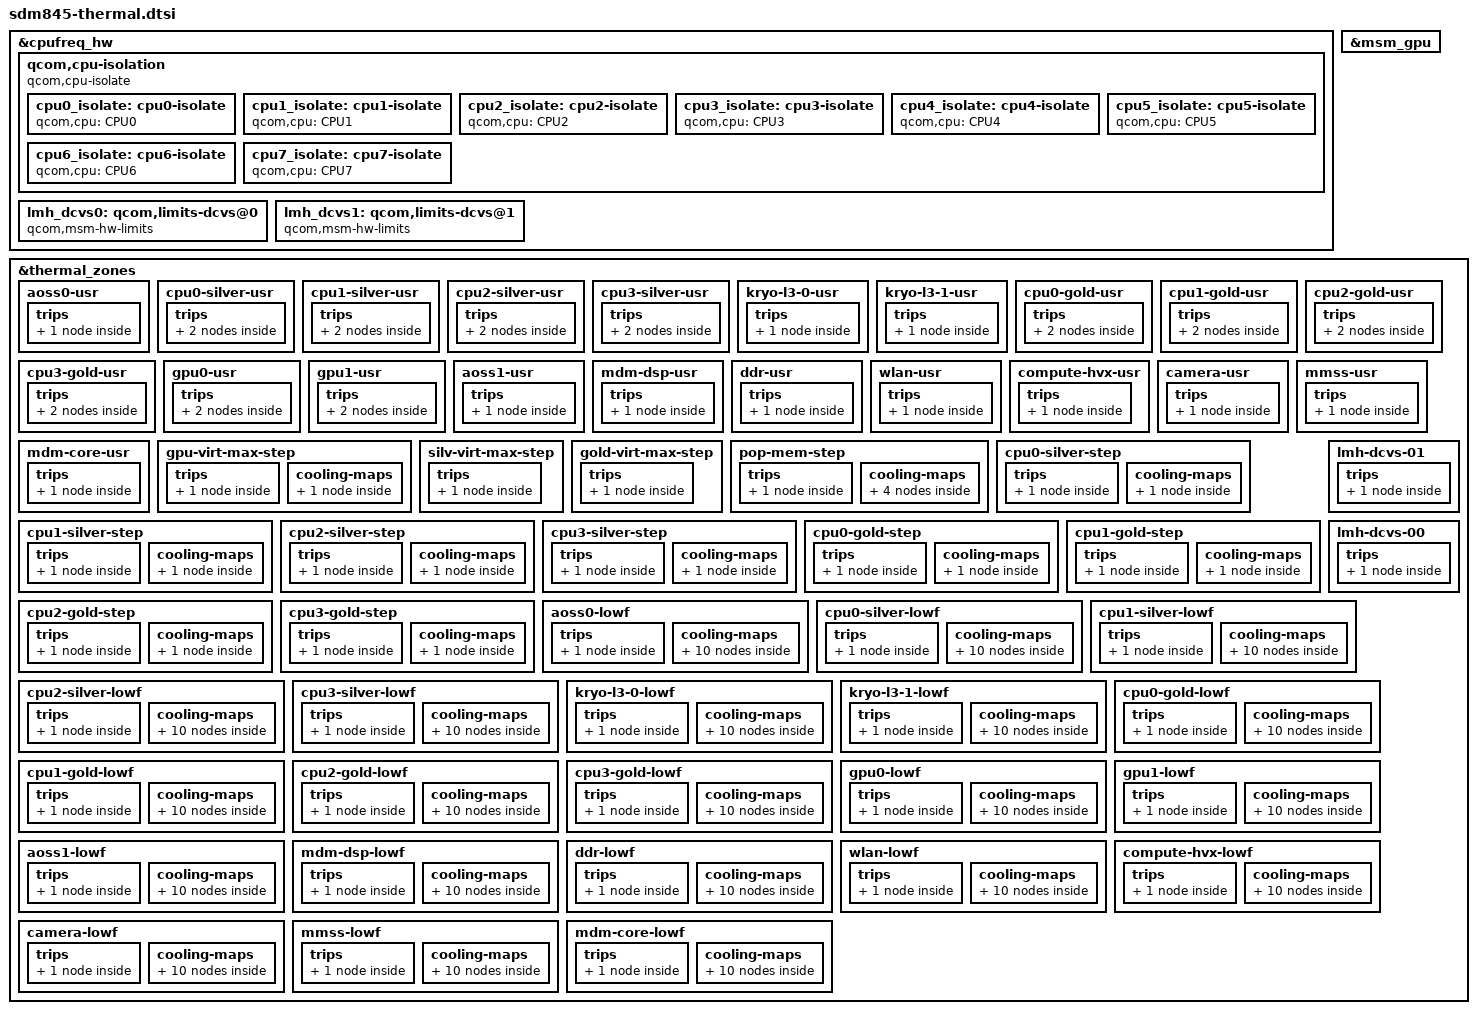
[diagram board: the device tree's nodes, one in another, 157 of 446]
// SPDX-License-Identifier: GPL-2.0-only
/*
 * Copyright (c) 2025, Pavel Dubrova <pashadubrova@gmail.com>
 */

#include <dt-bindings/thermal/thermal.h>

&cpufreq_hw {
	qcom,cpu-isolation {
		compatible = "qcom,cpu-isolate";
		cpu0_isolate: cpu0-isolate {
			qcom,cpu = <&CPU0>;
			#cooling-cells = <2>;
		};

		cpu1_isolate: cpu1-isolate {
			qcom,cpu = <&CPU1>;
			#cooling-cells = <2>;
		};

		cpu2_isolate: cpu2-isolate {
			qcom,cpu = <&CPU2>;
			#cooling-cells = <2>;
		};

		cpu3_isolate: cpu3-isolate {
			qcom,cpu = <&CPU3>;
			#cooling-cells = <2>;
		};

		cpu4_isolate: cpu4-isolate {
			qcom,cpu = <&CPU4>;
			#cooling-cells = <2>;
		};

		cpu5_isolate: cpu5-isolate {
			qcom,cpu = <&CPU5>;
			#cooling-cells = <2>;
		};

		cpu6_isolate: cpu6-isolate {
			qcom,cpu = <&CPU6>;
			#cooling-cells = <2>;
		};

		cpu7_isolate: cpu7-isolate {
			qcom,cpu = <&CPU7>;
			#cooling-cells = <2>;
		};
	};

	lmh_dcvs0: qcom,limits-dcvs@0 {
		compatible = "qcom,msm-hw-limits";
		interrupts = <GIC_SPI 32 IRQ_TYPE_LEVEL_HIGH>;
		reg = <0x17d78800 0x1000>,
		<0x17d43000 0x1000>;
		qcom,affinity = <0>;
		#thermal-sensor-cells = <0>;
		qcom,no-cooling-device-register;
		qcom,legacy-lmh-enable;
	};

	lmh_dcvs1: qcom,limits-dcvs@1 {
		compatible = "qcom,msm-hw-limits";
		interrupts = <GIC_SPI 33 IRQ_TYPE_LEVEL_HIGH>;
		qcom,affinity = <1>;
		reg = <0x17d70800 0x1000>,
		<0x17d45800 0x1000>;
		#thermal-sensor-cells = <0>;
		isens_vref_0p8-supply = <&pm8998_l1_ao>;
		isens-vref-0p8-settings = <880000 880000 20000>;
		qcom,no-cooling-device-register;
		qcom,legacy-lmh-enable;
	};
};

#include "sdm845-thermal-modem.dtsi"
#include "sdm845-thermal-overlay.dtsi"

&msm_gpu {
	#cooling-cells = <2>;
};

&thermal_zones {
	aoss0-usr {
		polling-delay-passive = <0>;
		polling-delay = <0>;
		thermal-governor = "user_space";
		thermal-sensors = <&tsens0 0>;
		wake-capable-sensor;
		trips {
			active-config0 {
				temperature = <125000>;
				hysteresis = <1000>;
				type = "passive";
			};
		};
	};

	cpu0-silver-usr {
		polling-delay-passive = <0>;
		polling-delay = <0>;
		thermal-governor = "user_space";
		thermal-sensors = <&tsens0 1>;
		wake-capable-sensor;
		trips {
			active-config0 {
				temperature = <125000>;
				hysteresis = <1000>;
				type = "passive";
			};

			thermal-hal-cfg {
				temperature = <115000>;
				hysteresis = <5000>;
				type = "passive";
			};
		};
	};

	cpu1-silver-usr {
		polling-delay-passive = <0>;
		polling-delay = <0>;
		thermal-governor = "user_space";
		thermal-sensors = <&tsens0 2>;
		wake-capable-sensor;
		trips {
			active-config0 {
				temperature = <125000>;
				hysteresis = <1000>;
				type = "passive";
			};

			thermal-hal-cfg {
				temperature = <115000>;
				hysteresis = <5000>;
				type = "passive";
			};
		};
	};

	cpu2-silver-usr {
		polling-delay-passive = <0>;
		polling-delay = <0>;
		thermal-governor = "user_space";
		thermal-sensors = <&tsens0 3>;
		wake-capable-sensor;
		trips {
			active-config0 {
				temperature = <125000>;
				hysteresis = <1000>;
				type = "passive";
			};

			thermal-hal-cfg {
				temperature = <115000>;
				hysteresis = <5000>;
				type = "passive";
			};
		};
	};

	cpu3-silver-usr {
		polling-delay-passive = <0>;
		polling-delay = <0>;
		thermal-sensors = <&tsens0 4>;
		wake-capable-sensor;
		thermal-governor = "user_space";
		trips {
			active-config0 {
				temperature = <125000>;
				hysteresis = <1000>;
				type = "passive";
			};

			thermal-hal-cfg {
				temperature = <115000>;
				hysteresis = <5000>;
				type = "passive";
			};
		};
	};

	kryo-l3-0-usr {
		polling-delay-passive = <0>;
		polling-delay = <0>;
		thermal-sensors = <&tsens0 5>;
		wake-capable-sensor;
		thermal-governor = "user_space";
		trips {
			active-config0 {
				temperature = <125000>;
				hysteresis = <1000>;
				type = "passive";
			};
		};
	};

	kryo-l3-1-usr {
		polling-delay-passive = <0>;
		polling-delay = <0>;
		thermal-sensors = <&tsens0 6>;
		wake-capable-sensor;
		thermal-governor = "user_space";
		trips {
			active-config0 {
				temperature = <125000>;
				hysteresis = <1000>;
				type = "passive";
			};
		};
	};

	cpu0-gold-usr {
		polling-delay-passive = <0>;
		polling-delay = <0>;
		thermal-sensors = <&tsens0 7>;
		wake-capable-sensor;
		thermal-governor = "user_space";
		trips {
			active-config0 {
				temperature = <125000>;
				hysteresis = <1000>;
				type = "passive";
			};

			thermal-hal-cfg {
				temperature = <115000>;
				hysteresis = <5000>;
				type = "passive";
			};
		};
	};

	cpu1-gold-usr {
		polling-delay-passive = <0>;
		polling-delay = <0>;
		thermal-sensors = <&tsens0 8>;
		wake-capable-sensor;
		thermal-governor = "user_space";
		trips {
			active-config0 {
				temperature = <125000>;
				hysteresis = <1000>;
				type = "passive";
			};

			thermal-hal-cfg {
				temperature = <115000>;
				hysteresis = <5000>;
				type = "passive";
			};
		};
	};

	cpu2-gold-usr {
		polling-delay-passive = <0>;
		polling-delay = <0>;
		thermal-sensors = <&tsens0 9>;
		wake-capable-sensor;
		thermal-governor = "user_space";
		trips {
			active-config0 {
				temperature = <125000>;
				hysteresis = <1000>;
				type = "passive";
			};

			thermal-hal-cfg {
				temperature = <115000>;
				hysteresis = <5000>;
				type = "passive";
			};
		};
	};

	cpu3-gold-usr {
		polling-delay-passive = <0>;
		polling-delay = <0>;
		thermal-sensors = <&tsens0 10>;
		wake-capable-sensor;
		thermal-governor = "user_space";
		trips {
			active-config0 {
				temperature = <125000>;
				hysteresis = <1000>;
				type = "passive";
			};

			thermal-hal-cfg {
				temperature = <115000>;
				hysteresis = <5000>;
				type = "passive";
			};
		};
	};

	gpu0-usr {
		polling-delay-passive = <0>;
		polling-delay = <0>;
		thermal-sensors = <&tsens0 11>;
		wake-capable-sensor;
		thermal-governor = "user_space";
		trips {
			active-config0 {
				temperature = <125000>;
				hysteresis = <1000>;
				type = "passive";
			};

			thermal-hal-cfg {
				temperature = <115000>;
				hysteresis = <5000>;
				type = "passive";
			};
		};
	};

	gpu1-usr {
		polling-delay-passive = <0>;
		polling-delay = <0>;
		thermal-governor = "user_space";
		thermal-sensors = <&tsens0 12>;
		wake-capable-sensor;
		trips {
			active-config0 {
				temperature = <125000>;
				hysteresis = <1000>;
				type = "passive";
			};

			thermal-hal-cfg {
				temperature = <115000>;
				hysteresis = <5000>;
				type = "passive";
			};
		};
	};

	aoss1-usr {
		polling-delay-passive = <0>;
		polling-delay = <0>;
		thermal-sensors = <&tsens1 0>;
		wake-capable-sensor;
		thermal-governor = "user_space";
		trips {
			active-config0 {
				temperature = <125000>;
				hysteresis = <1000>;
				type = "passive";
			};
		};
	};

	mdm-dsp-usr {
		polling-delay-passive = <0>;
		polling-delay = <0>;
		thermal-sensors = <&tsens1 1>;
		wake-capable-sensor;
		thermal-governor = "user_space";
		trips {
			active-config0 {
				temperature = <125000>;
				hysteresis = <1000>;
				type = "passive";
			};
		};
	};



	ddr-usr {
		polling-delay-passive = <0>;
		polling-delay = <0>;
		thermal-sensors = <&tsens1 2>;
		wake-capable-sensor;
		thermal-governor = "user_space";
		trips {
			active-config0 {
				temperature = <125000>;
				hysteresis = <1000>;
				type = "passive";
			};
		};
	};

	wlan-usr {
		polling-delay-passive = <0>;
		polling-delay = <0>;
		thermal-sensors = <&tsens1 3>;
		wake-capable-sensor;
		thermal-governor = "user_space";
		trips {
			active-config0 {
				temperature = <125000>;
				hysteresis = <1000>;
				type = "passive";
			};
		};
	};

	compute-hvx-usr {
		polling-delay-passive = <0>;
		polling-delay = <0>;
		thermal-sensors = <&tsens1 4>;
		wake-capable-sensor;
		thermal-governor = "user_space";
		trips {
			active-config0 {
				temperature = <125000>;
				hysteresis = <1000>;
				type = "passive";
			};
		};
	};

	camera-usr {
		polling-delay-passive = <0>;
		polling-delay = <0>;
		thermal-sensors = <&tsens1 5>;
		wake-capable-sensor;
		thermal-governor = "user_space";
		trips {
			active-config0 {
				temperature = <125000>;
				hysteresis = <1000>;
				type = "passive";
			};
		};
	};

	mmss-usr {
		polling-delay-passive = <0>;
		polling-delay = <0>;
		thermal-sensors = <&tsens1 6>;
		wake-capable-sensor;
		thermal-governor = "user_space";
		trips {
			active-config0 {
				temperature = <125000>;
				hysteresis = <1000>;
				type = "passive";
			};
		};
	};

	mdm-core-usr {
		polling-delay-passive = <0>;
		polling-delay = <0>;
		thermal-sensors = <&tsens1 7>;
		wake-capable-sensor;
		thermal-governor = "user_space";
		trips {
			active-config0 {
				temperature = <125000>;
				hysteresis = <1000>;
				type = "passive";
			};
		};
	};

	gpu-virt-max-step {
		polling-delay-passive = <10>;
		polling-delay = <100>;
		thermal-governor = "step_wise";
		wake-capable-sensor;
		trips {
			gpu_trip0: gpu-trip0 {
				temperature = <95000>;
				hysteresis = <0>;
				type = "passive";
			};
		};
		cooling-maps {
			gpu_cdev0 {
				trip = <&gpu_trip0>;
				cooling-device =
				<&msm_gpu 0 THERMAL_NO_LIMIT>;
			};
		};
	};

	silv-virt-max-step {
		polling-delay-passive = <0>;
		polling-delay = <0>;
		thermal-governor = "step_wise";
		wake-capable-sensor;
		trips {
			silver-trip {
				temperature = <120000>;
				hysteresis = <0>;
				type = "passive";
			};
		};
	};

	gold-virt-max-step {
		polling-delay-passive = <0>;
		polling-delay = <0>;
		thermal-governor = "step_wise";
		wake-capable-sensor;
		trips {
			gold-trip {
				temperature = <120000>;
				hysteresis = <0>;
				type = "passive";
			};
		};
	};

	pop-mem-step {
		polling-delay-passive = <10>;
		polling-delay = <0>;
		thermal-sensors = <&tsens1 2>;
		wake-capable-sensor;
		thermal-governor = "step_wise";
		trips {
			pop_trip: pop-trip {
				temperature = <95000>;
				hysteresis = <0>;
				type = "passive";
			};
		};
		cooling-maps {
			pop_cdev4 {
				trip = <&pop_trip>;
				cooling-device =
				<&CPU4 THERMAL_NO_LIMIT
				(THERMAL_MAX_LIMIT-1)>;
			};
			pop_cdev5 {
				trip = <&pop_trip>;
				cooling-device =
				<&CPU5 THERMAL_NO_LIMIT
				(THERMAL_MAX_LIMIT-1)>;
			};
			pop_cdev6 {
				trip = <&pop_trip>;
				cooling-device =
				<&CPU6 THERMAL_NO_LIMIT
				(THERMAL_MAX_LIMIT-1)>;
			};
			pop_cdev7 {
				trip = <&pop_trip>;
				cooling-device =
				<&CPU7 THERMAL_NO_LIMIT
				(THERMAL_MAX_LIMIT-1)>;
			};
		};
	};

	cpu0-silver-step {
		polling-delay-passive = <100>;
		polling-delay = <0>;
		thermal-sensors = <&tsens0 1>;
		wake-capable-sensor;
		thermal-governor = "step_wise";
		trips {
			emerg_config0: emerg-config0 {
				temperature = <110000>;
				hysteresis = <10000>;
				type = "passive";
			};
		};
		cooling-maps {
			emerg_cdev0 {
				trip = <&emerg_config0>;
				cooling-device = <&cpu0_isolate 1 1>;
			};
		};
	};

	cpu1-silver-step {
		polling-delay-passive = <100>;
		polling-delay = <0>;
		thermal-sensors = <&tsens0 2>;
		wake-capable-sensor;
		thermal-governor = "step_wise";
		trips {
			emerg_config1: emerg-config1 {
				temperature = <110000>;
				hysteresis = <10000>;
				type = "passive";
			};
		};
		cooling-maps {
			emerg_cdev1 {
				trip = <&emerg_config1>;
				cooling-device = <&cpu1_isolate 1 1>;
			};
		};
	};

	cpu2-silver-step {
		polling-delay-passive = <100>;
		polling-delay = <0>;
		thermal-sensors = <&tsens0 3>;
		wake-capable-sensor;
		thermal-governor = "step_wise";
		trips {
			emerg_config2: emerg-config2 {
				temperature = <110000>;
				hysteresis = <10000>;
				type = "passive";
			};
		};
		cooling-maps {
			emerg_cdev2 {
				trip = <&emerg_config2>;
				cooling-device = <&cpu2_isolate 1 1>;
			};
		};
	};

	cpu3-silver-step {
		polling-delay-passive = <100>;
		polling-delay = <0>;
		thermal-sensors = <&tsens0 4>;
		wake-capable-sensor;
		thermal-governor = "step_wise";
		trips {
			emerg_config3: emerg-config3 {
				temperature = <110000>;
				hysteresis = <10000>;
				type = "passive";
			};
		};
		cooling-maps {
			emerg_cdev3 {
				trip = <&emerg_config3>;
				cooling-device = <&cpu3_isolate 1 1>;
			};
		};
	};

	cpu0-gold-step {
		polling-delay-passive = <100>;
		polling-delay = <0>;
		thermal-sensors = <&tsens0 7>;
		wake-capable-sensor;
		thermal-governor = "step_wise";
		trips {
			emerg_config4: emerg-config4 {
				temperature = <110000>;
				hysteresis = <10000>;
				type = "passive";
			};
		};
		cooling-maps {
			emerg_cdev4 {
				trip = <&emerg_config4>;
				cooling-device = <&cpu4_isolate 1 1>;
			};
		};
	};

	cpu1-gold-step {
		polling-delay-passive = <100>;
		polling-delay = <0>;
		thermal-sensors = <&tsens0 8>;
		wake-capable-sensor;
		thermal-governor = "step_wise";
		trips {
			emerg_config5: emerg-config5 {
				temperature = <110000>;
				hysteresis = <10000>;
				type = "passive";
			};
		};
		cooling-maps {
			emerg_cdev5 {
				trip = <&emerg_config5>;
				cooling-device = <&cpu5_isolate 1 1>;
			};
		};
	};

	cpu2-gold-step {
		polling-delay-passive = <100>;
		polling-delay = <0>;
		thermal-sensors = <&tsens0 9>;
		wake-capable-sensor;
		thermal-governor = "step_wise";
		trips {
			emerg_config6: emerg-config6 {
				temperature = <110000>;
				hysteresis = <10000>;
				type = "passive";
			};
		};
		cooling-maps {
			emerg_cdev6 {
				trip = <&emerg_config6>;
				cooling-device = <&cpu6_isolate 1 1>;
			};
		};
	};

	cpu3-gold-step {
		polling-delay-passive = <100>;
		polling-delay = <0>;
		thermal-sensors = <&tsens0 10>;
		wake-capable-sensor;
		thermal-governor = "step_wise";
		trips {
			emerg_config7: emerg-config7 {
				temperature = <110000>;
				hysteresis = <10000>;
				type = "passive";
			};
		};
		cooling-maps {
			emerg_cdev7 {
				trip = <&emerg_config7>;
				cooling-device = <&cpu7_isolate 1 1>;
			};
		};
	};

	lmh-dcvs-01 {
		polling-delay-passive = <0>;
		polling-delay = <0>;
		thermal-governor = "user_space";
		thermal-sensors = <&lmh_dcvs1>;
		wake-capable-sensor;

		trips {
			active-config {
				temperature = <95000>;
				hysteresis = <30000>;
				type = "passive";
			};
		};
	};

	lmh-dcvs-00 {
		polling-delay-passive = <0>;
		polling-delay = <0>;
		thermal-governor = "user_space";
		thermal-sensors = <&lmh_dcvs0>;
		wake-capable-sensor;

		trips {
			active-config {
				temperature = <95000>;
				hysteresis = <30000>;
				type = "passive";
			};
		};
	};
};

&thermal_zones {
		aoss0-lowf {
		polling-delay-passive = <0>;
		polling-delay = <0>;
		thermal-governor = "low_limits_floor";
		thermal-sensors = <&tsens0 0>;
		wake-capable-sensor;
		tracks-low;
		trips {
			aoss0_trip: aoss0-trip {
				temperature = <5000>;
				hysteresis = <5000>;
				type = "passive";
			};
		};
		cooling-maps {
			cpu0_vdd_cdev {
				trip = <&aoss0_trip>;
				cooling-device = <&CPU0 4 4>;
			};
			cpu4_vdd_cdev {
				trip = <&aoss0_trip>;
				cooling-device = <&CPU4 9 9>;
			};
			gpu_vdd_cdev {
				trip = <&aoss0_trip>;
				cooling-device = <&msm_gpu 1 1>;
			};
			cx_vdd_cdev {
				trip = <&aoss0_trip>;
				cooling-device = <&cx_cdev 0 0>;
			};
			mx_vdd_cdev {
				trip = <&aoss0_trip>;
				cooling-device = <&mx_cdev 0 0>;
			};
			ebi_vdd_cdev {
				trip = <&aoss0_trip>;
				cooling-device = <&ebi_cdev 0 0>;
			};
			modem_vdd_cdev {
				trip = <&aoss0_trip>;
				cooling-device = <&modem_vdd 0 0>;
			};
			adsp_vdd_cdev {
				trip = <&aoss0_trip>;
				cooling-device = <&adsp_vdd 0 0>;
			};
			cdsp_vdd_cdev {
				trip = <&aoss0_trip>;
				cooling-device = <&cdsp_vdd 0 0>;
			};
			slpi_vdd_cdev {
				trip = <&aoss0_trip>;
				cooling-device = <&slpi_vdd 0 0>;
			};
		};
	};

	cpu0-silver-lowf {
		polling-delay-passive = <0>;
		polling-delay = <0>;
		thermal-governor = "low_limits_floor";
		thermal-sensors = <&tsens0 1>;
		wake-capable-sensor;
		tracks-low;
		trips {
			cpu0_trip: cpu0-trip {
				temperature = <5000>;
				hysteresis = <5000>;
				type = "passive";
			};
		};
		cooling-maps {
			cpu0_vdd_cdev {
				trip = <&cpu0_trip>;
				cooling-device = <&CPU0 4 4>;
			};
			cpu4_vdd_cdev {
				trip = <&cpu0_trip>;
				cooling-device = <&CPU4 9 9>;
			};
			gpu_vdd_cdev {
				trip = <&cpu0_trip>;
				cooling-device = <&msm_gpu 1 1>;
			};
			cx_vdd_cdev {
				trip = <&cpu0_trip>;
				cooling-device = <&cx_cdev 0 0>;
			};
			mx_vdd_cdev {
				trip = <&cpu0_trip>;
				cooling-device = <&mx_cdev 0 0>;
			};
			ebi_vdd_cdev {
				trip = <&cpu0_trip>;
				cooling-device = <&ebi_cdev 0 0>;
			};
			modem_vdd_cdev {
				trip = <&cpu0_trip>;
				cooling-device = <&modem_vdd 0 0>;
			};
			adsp_vdd_cdev {
				trip = <&cpu0_trip>;
				cooling-device = <&adsp_vdd 0 0>;
			};
			cdsp_vdd_cdev {
				trip = <&cpu0_trip>;
				cooling-device = <&cdsp_vdd 0 0>;
			};
			slpi_vdd_cdev {
				trip = <&cpu0_trip>;
				cooling-device = <&slpi_vdd 0 0>;
			};
		};
	};

	cpu1-silver-lowf {
		polling-delay-passive = <0>;
		polling-delay = <0>;
		thermal-governor = "low_limits_floor";
		thermal-sensors = <&tsens0 2>;
		wake-capable-sensor;
		tracks-low;
		trips {
			cpu1_trip: cpu1-trip {
				temperature = <5000>;
				hysteresis = <5000>;
				type = "passive";
			};
		};
		cooling-maps {
			cpu0_vdd_cdev {
				trip = <&cpu1_trip>;
				cooling-device = <&CPU0 4 4>;
			};
			cpu4_vdd_cdev {
				trip = <&cpu1_trip>;
				cooling-device = <&CPU4 9 9>;
			};
			gpu_vdd_cdev {
				trip = <&cpu1_trip>;
				cooling-device = <&msm_gpu 1 1>;
			};
			cx_vdd_cdev {
				trip = <&cpu1_trip>;
				cooling-device = <&cx_cdev 0 0>;
			};
			mx_vdd_cdev {
				trip = <&cpu1_trip>;
				cooling-device = <&mx_cdev 0 0>;
			};
			ebi_vdd_cdev {
				trip = <&cpu1_trip>;
				cooling-device = <&ebi_cdev 0 0>;
			};
			modem_vdd_cdev {
				trip = <&cpu1_trip>;
				cooling-device = <&modem_vdd 0 0>;
			};
			adsp_vdd_cdev {
				trip = <&cpu1_trip>;
				cooling-device = <&adsp_vdd 0 0>;
			};
			cdsp_vdd_cdev {
				trip = <&cpu1_trip>;
				cooling-device = <&cdsp_vdd 0 0>;
			};
			slpi_vdd_cdev {
				trip = <&cpu1_trip>;
				cooling-device = <&slpi_vdd 0 0>;
			};
		};
	};

	cpu2-silver-lowf {
		polling-delay-passive = <0>;
		polling-delay = <0>;
		thermal-governor = "low_limits_floor";
		thermal-sensors = <&tsens0 3>;
		wake-capable-sensor;
		tracks-low;
		trips {
			cpu2_trip: cpu2-trip {
				temperature = <5000>;
				hysteresis = <5000>;
				type = "passive";
			};
		};
		cooling-maps {
			cpu0_vdd_cdev {
				trip = <&cpu2_trip>;
				cooling-device = <&CPU0 4 4>;
			};
			cpu4_vdd_cdev {
				trip = <&cpu2_trip>;
				cooling-device = <&CPU4 9 9>;
			};
			gpu_vdd_cdev {
				trip = <&cpu2_trip>;
				cooling-device = <&msm_gpu 1 1>;
			};
			cx_vdd_cdev {
				trip = <&cpu2_trip>;
				cooling-device = <&cx_cdev 0 0>;
			};
			mx_vdd_cdev {
				trip = <&cpu2_trip>;
				cooling-device = <&mx_cdev 0 0>;
			};
			ebi_vdd_cdev {
				trip = <&cpu2_trip>;
				cooling-device = <&ebi_cdev 0 0>;
			};
			modem_vdd_cdev {
				trip = <&cpu2_trip>;
				cooling-device = <&modem_vdd 0 0>;
			};
			adsp_vdd_cdev {
				trip = <&cpu2_trip>;
				cooling-device = <&adsp_vdd 0 0>;
			};
			cdsp_vdd_cdev {
				trip = <&cpu2_trip>;
				cooling-device = <&cdsp_vdd 0 0>;
			};
			slpi_vdd_cdev {
				trip = <&cpu2_trip>;
				cooling-device = <&slpi_vdd 0 0>;
			};
		};
	};

	cpu3-silver-lowf {
		polling-delay-passive = <0>;
		polling-delay = <0>;
		thermal-governor = "low_limits_floor";
		thermal-sensors = <&tsens0 4>;
		wake-capable-sensor;
		tracks-low;
		trips {
			cpu3_trip: cpu3-trip {
				temperature = <5000>;
				hysteresis = <5000>;
				type = "passive";
			};
		};
		cooling-maps {
			cpu0_vdd_cdev {
				trip = <&cpu3_trip>;
				cooling-device = <&CPU0 4 4>;
			};
			cpu4_vdd_cdev {
				trip = <&cpu3_trip>;
				cooling-device = <&CPU4 9 9>;
			};
			gpu_vdd_cdev {
				trip = <&cpu3_trip>;
				cooling-device = <&msm_gpu 1 1>;
			};
			cx_vdd_cdev {
				trip = <&cpu3_trip>;
				cooling-device = <&cx_cdev 0 0>;
			};
			mx_vdd_cdev {
				trip = <&cpu3_trip>;
				cooling-device = <&mx_cdev 0 0>;
			};
			ebi_vdd_cdev {
				trip = <&cpu3_trip>;
				cooling-device = <&ebi_cdev 0 0>;
			};
			modem_vdd_cdev {
				trip = <&cpu3_trip>;
				cooling-device = <&modem_vdd 0 0>;
			};
			adsp_vdd_cdev {
				trip = <&cpu3_trip>;
				cooling-device = <&adsp_vdd 0 0>;
			};
			cdsp_vdd_cdev {
				trip = <&cpu3_trip>;
				cooling-device = <&cdsp_vdd 0 0>;
			};
			slpi_vdd_cdev {
				trip = <&cpu3_trip>;
				cooling-device = <&slpi_vdd 0 0>;
			};
		};
	};

	kryo-l3-0-lowf {
		polling-delay-passive = <0>;
		polling-delay = <0>;
		thermal-governor = "low_limits_floor";
		thermal-sensors = <&tsens0 5>;
		wake-capable-sensor;
		tracks-low;
		trips {
			l3_0_trip: l3-0-trip {
				temperature = <5000>;
				hysteresis = <5000>;
				type = "passive";
			};
		};
		cooling-maps {
			cpu0_vdd_cdev {
				trip = <&l3_0_trip>;
				cooling-device = <&CPU0 4 4>;
			};
			cpu4_vdd_cdev {
				trip = <&l3_0_trip>;
				cooling-device = <&CPU4 9 9>;
			};
			gpu_vdd_cdev {
				trip = <&l3_0_trip>;
				cooling-device = <&msm_gpu 1 1>;
			};
			cx_vdd_cdev {
				trip = <&l3_0_trip>;
				cooling-device = <&cx_cdev 0 0>;
			};
			mx_vdd_cdev {
				trip = <&l3_0_trip>;
				cooling-device = <&mx_cdev 0 0>;
			};
			ebi_vdd_cdev {
				trip = <&l3_0_trip>;
				cooling-device = <&ebi_cdev 0 0>;
			};
			modem_vdd_cdev {
				trip = <&l3_0_trip>;
				cooling-device = <&modem_vdd 0 0>;
			};
			adsp_vdd_cdev {
				trip = <&l3_0_trip>;
				cooling-device = <&adsp_vdd 0 0>;
			};
			cdsp_vdd_cdev {
				trip = <&l3_0_trip>;
				cooling-device = <&cdsp_vdd 0 0>;
			};
			slpi_vdd_cdev {
				trip = <&l3_0_trip>;
				cooling-device = <&slpi_vdd 0 0>;
			};
		};
	};

	kryo-l3-1-lowf {
		polling-delay-passive = <0>;
		polling-delay = <0>;
		thermal-governor = "low_limits_floor";
		thermal-sensors = <&tsens0 6>;
		wake-capable-sensor;
		tracks-low;
		trips {
			l3_1_trip: l3-1-trip {
				temperature = <5000>;
				hysteresis = <5000>;
				type = "passive";
			};
		};
		cooling-maps {
			cpu0_vdd_cdev {
				trip = <&l3_1_trip>;
				cooling-device = <&CPU0 4 4>;
			};
			cpu4_vdd_cdev {
				trip = <&l3_1_trip>;
				cooling-device = <&CPU4 9 9>;
			};
			gpu_vdd_cdev {
				trip = <&l3_1_trip>;
				cooling-device = <&msm_gpu 1 1>;
			};
			cx_vdd_cdev {
				trip = <&l3_1_trip>;
				cooling-device = <&cx_cdev 0 0>;
			};
			mx_vdd_cdev {
				trip = <&l3_1_trip>;
				cooling-device = <&mx_cdev 0 0>;
			};
			ebi_vdd_cdev {
				trip = <&l3_1_trip>;
				cooling-device = <&ebi_cdev 0 0>;
			};
			modem_vdd_cdev {
				trip = <&l3_1_trip>;
				cooling-device = <&modem_vdd 0 0>;
			};
			adsp_vdd_cdev {
				trip = <&l3_1_trip>;
				cooling-device = <&adsp_vdd 0 0>;
			};
			cdsp_vdd_cdev {
				trip = <&l3_1_trip>;
				cooling-device = <&cdsp_vdd 0 0>;
			};
			slpi_vdd_cdev {
				trip = <&l3_1_trip>;
				cooling-device = <&slpi_vdd 0 0>;
			};
		};
	};

	cpu0-gold-lowf {
		polling-delay-passive = <0>;
		polling-delay = <0>;
		thermal-governor = "low_limits_floor";
		thermal-sensors = <&tsens0 7>;
		wake-capable-sensor;
		tracks-low;
		trips {
			cpug0_trip: cpug0-trip {
				temperature = <5000>;
				hysteresis = <5000>;
				type = "passive";
			};
		};
		cooling-maps {
			cpu0_vdd_cdev {
				trip = <&cpug0_trip>;
				cooling-device = <&CPU0 4 4>;
			};
			cpu4_vdd_cdev {
				trip = <&cpug0_trip>;
				cooling-device = <&CPU4 9 9>;
			};
			gpu_vdd_cdev {
				trip = <&cpug0_trip>;
				cooling-device = <&msm_gpu 1 1>;
			};
			cx_vdd_cdev {
				trip = <&cpug0_trip>;
				cooling-device = <&cx_cdev 0 0>;
			};
			mx_vdd_cdev {
				trip = <&cpug0_trip>;
				cooling-device = <&mx_cdev 0 0>;
			};
			ebi_vdd_cdev {
				trip = <&cpug0_trip>;
				cooling-device = <&ebi_cdev 0 0>;
			};
			modem_vdd_cdev {
				trip = <&cpug0_trip>;
				cooling-device = <&modem_vdd 0 0>;
			};
			adsp_vdd_cdev {
				trip = <&cpug0_trip>;
				cooling-device = <&adsp_vdd 0 0>;
			};
			cdsp_vdd_cdev {
				trip = <&cpug0_trip>;
				cooling-device = <&cdsp_vdd 0 0>;
			};
			slpi_vdd_cdev {
				trip = <&cpug0_trip>;
				cooling-device = <&slpi_vdd 0 0>;
			};
		};
	};

	cpu1-gold-lowf {
		polling-delay-passive = <0>;
		polling-delay = <0>;
		thermal-governor = "low_limits_floor";
		thermal-sensors = <&tsens0 8>;
		wake-capable-sensor;
		tracks-low;
		trips {
			cpug1_trip: cpug1-trip {
				temperature = <5000>;
				hysteresis = <5000>;
				type = "passive";
			};
		};
		cooling-maps {
			cpu0_vdd_cdev {
				trip = <&cpug1_trip>;
				cooling-device = <&CPU0 4 4>;
			};
			cpu4_vdd_cdev {
				trip = <&cpug1_trip>;
				cooling-device = <&CPU4 9 9>;
			};
			gpu_vdd_cdev {
				trip = <&cpug1_trip>;
				cooling-device = <&msm_gpu 1 1>;
			};
			cx_vdd_cdev {
				trip = <&cpug1_trip>;
				cooling-device = <&cx_cdev 0 0>;
			};
			mx_vdd_cdev {
				trip = <&cpug1_trip>;
				cooling-device = <&mx_cdev 0 0>;
			};
			ebi_vdd_cdev {
				trip = <&cpug1_trip>;
				cooling-device = <&ebi_cdev 0 0>;
			};
			modem_vdd_cdev {
				trip = <&cpug1_trip>;
				cooling-device = <&modem_vdd 0 0>;
			};
			adsp_vdd_cdev {
				trip = <&cpug1_trip>;
				cooling-device = <&adsp_vdd 0 0>;
			};
			cdsp_vdd_cdev {
				trip = <&cpug1_trip>;
				cooling-device = <&cdsp_vdd 0 0>;
			};
			slpi_vdd_cdev {
				trip = <&cpug1_trip>;
				cooling-device = <&slpi_vdd 0 0>;
			};
		};
	};

	cpu2-gold-lowf {
		polling-delay-passive = <0>;
		polling-delay = <0>;
		thermal-governor = "low_limits_floor";
		thermal-sensors = <&tsens0 9>;
		wake-capable-sensor;
		tracks-low;
		trips {
			cpug2_trip: cpug2-trip {
				temperature = <5000>;
				hysteresis = <5000>;
				type = "passive";
			};
		};
		cooling-maps {
			cpu0_vdd_cdev {
				trip = <&cpug2_trip>;
				cooling-device = <&CPU0 4 4>;
			};
			cpu4_vdd_cdev {
				trip = <&cpug2_trip>;
				cooling-device = <&CPU4 9 9>;
			};
			gpu_vdd_cdev {
				trip = <&cpug2_trip>;
				cooling-device = <&msm_gpu 1 1>;
			};
			cx_vdd_cdev {
				trip = <&cpug2_trip>;
				cooling-device = <&cx_cdev 0 0>;
			};
			mx_vdd_cdev {
				trip = <&cpug2_trip>;
				cooling-device = <&mx_cdev 0 0>;
			};
			ebi_vdd_cdev {
				trip = <&cpug2_trip>;
				cooling-device = <&ebi_cdev 0 0>;
			};
			modem_vdd_cdev {
				trip = <&cpug2_trip>;
				cooling-device = <&modem_vdd 0 0>;
			};
			adsp_vdd_cdev {
				trip = <&cpug2_trip>;
				cooling-device = <&adsp_vdd 0 0>;
			};
			cdsp_vdd_cdev {
				trip = <&cpug2_trip>;
				cooling-device = <&cdsp_vdd 0 0>;
			};
			slpi_vdd_cdev {
				trip = <&cpug2_trip>;
				cooling-device = <&slpi_vdd 0 0>;
			};
		};
	};

	cpu3-gold-lowf {
		polling-delay-passive = <0>;
		polling-delay = <0>;
		thermal-governor = "low_limits_floor";
		thermal-sensors = <&tsens0 10>;
		wake-capable-sensor;
		tracks-low;
		trips {
			cpug3_trip: cpug3-trip {
				temperature = <5000>;
				hysteresis = <5000>;
				type = "passive";
			};
		};
		cooling-maps {
			cpu0_vdd_cdev {
				trip = <&cpug3_trip>;
				cooling-device = <&CPU0 4 4>;
			};
			cpu4_vdd_cdev {
				trip = <&cpug3_trip>;
				cooling-device = <&CPU4 9 9>;
			};
			gpu_vdd_cdev {
				trip = <&cpug3_trip>;
				cooling-device = <&msm_gpu 1 1>;
			};
			cx_vdd_cdev {
				trip = <&cpug3_trip>;
				cooling-device = <&cx_cdev 0 0>;
			};
			mx_vdd_cdev {
				trip = <&cpug3_trip>;
				cooling-device = <&mx_cdev 0 0>;
			};
			ebi_vdd_cdev {
				trip = <&cpug3_trip>;
				cooling-device = <&ebi_cdev 0 0>;
			};
			modem_vdd_cdev {
				trip = <&cpug3_trip>;
				cooling-device = <&modem_vdd 0 0>;
			};
			adsp_vdd_cdev {
				trip = <&cpug3_trip>;
				cooling-device = <&adsp_vdd 0 0>;
			};
			cdsp_vdd_cdev {
				trip = <&cpug3_trip>;
				cooling-device = <&cdsp_vdd 0 0>;
			};
			slpi_vdd_cdev {
				trip = <&cpug3_trip>;
				cooling-device = <&slpi_vdd 0 0>;
			};
		};
	};

	gpu0-lowf {
		polling-delay-passive = <0>;
		polling-delay = <0>;
		thermal-governor = "low_limits_floor";
		thermal-sensors = <&tsens0 11>;
		wake-capable-sensor;
		tracks-low;
		trips {
			gpu0_trip_l: gpu0-trip {
				temperature = <5000>;
				hysteresis = <5000>;
				type = "passive";
			};
		};
		cooling-maps {
			cpu0_vdd_cdev {
				trip = <&gpu0_trip_l>;
				cooling-device = <&CPU0 4 4>;
			};
			cpu4_vdd_cdev {
				trip = <&gpu0_trip_l>;
				cooling-device = <&CPU4 9 9>;
			};
			gpu_vdd_cdev {
				trip = <&gpu0_trip_l>;
				cooling-device = <&msm_gpu 1 1>;
			};
			cx_vdd_cdev {
				trip = <&gpu0_trip_l>;
				cooling-device = <&cx_cdev 0 0>;
			};
			mx_vdd_cdev {
				trip = <&gpu0_trip_l>;
				cooling-device = <&mx_cdev 0 0>;
			};
			ebi_vdd_cdev {
				trip = <&gpu0_trip_l>;
				cooling-device = <&ebi_cdev 0 0>;
			};
			modem_vdd_cdev {
				trip = <&gpu0_trip_l>;
				cooling-device = <&modem_vdd 0 0>;
			};
			adsp_vdd_cdev {
				trip = <&gpu0_trip_l>;
				cooling-device = <&adsp_vdd 0 0>;
			};
			cdsp_vdd_cdev {
				trip = <&gpu0_trip_l>;
				cooling-device = <&cdsp_vdd 0 0>;
			};
			slpi_vdd_cdev {
				trip = <&gpu0_trip_l>;
				cooling-device = <&slpi_vdd 0 0>;
			};
		};
	};

	gpu1-lowf {
		polling-delay-passive = <0>;
		polling-delay = <0>;
		thermal-governor = "low_limits_floor";
		thermal-sensors = <&tsens0 12>;
		wake-capable-sensor;
		tracks-low;
		trips {
			gpu1_trip_l: gpu1-trip_l {
				temperature = <5000>;
				hysteresis = <5000>;
				type = "passive";
			};
		};
		cooling-maps {
			cpu0_vdd_cdev {
				trip = <&gpu1_trip_l>;
				cooling-device = <&CPU0 4 4>;
			};
			cpu4_vdd_cdev {
				trip = <&gpu1_trip_l>;
				cooling-device = <&CPU4 9 9>;
			};
			gpu_vdd_cdev {
				trip = <&gpu1_trip_l>;
				cooling-device = <&msm_gpu 1 1>;
			};
			cx_vdd_cdev {
				trip = <&gpu1_trip_l>;
				cooling-device = <&cx_cdev 0 0>;
			};
			mx_vdd_cdev {
				trip = <&gpu1_trip_l>;
				cooling-device = <&mx_cdev 0 0>;
			};
			ebi_vdd_cdev {
				trip = <&gpu1_trip_l>;
				cooling-device = <&ebi_cdev 0 0>;
			};
			modem_vdd_cdev {
				trip = <&gpu1_trip_l>;
				cooling-device = <&modem_vdd 0 0>;
			};
			adsp_vdd_cdev {
				trip = <&gpu1_trip_l>;
				cooling-device = <&adsp_vdd 0 0>;
			};
			cdsp_vdd_cdev {
				trip = <&gpu1_trip_l>;
				cooling-device = <&cdsp_vdd 0 0>;
			};
			slpi_vdd_cdev {
				trip = <&gpu1_trip_l>;
				cooling-device = <&slpi_vdd 0 0>;
			};
		};
	};

	aoss1-lowf {
		polling-delay-passive = <0>;
		polling-delay = <0>;
		thermal-governor = "low_limits_floor";
		thermal-sensors = <&tsens1 0>;
		wake-capable-sensor;
		tracks-low;
		trips {
			aoss1_trip: aoss1-trip {
				temperature = <5000>;
				hysteresis = <5000>;
				type = "passive";
			};
		};
		cooling-maps {
			cpu0_vdd_cdev {
				trip = <&aoss1_trip>;
				cooling-device = <&CPU0 4 4>;
			};
			cpu4_vdd_cdev {
				trip = <&aoss1_trip>;
				cooling-device = <&CPU4 9 9>;
			};
			gpu_vdd_cdev {
				trip = <&aoss1_trip>;
				cooling-device = <&msm_gpu 1 1>;
			};
			cx_vdd_cdev {
				trip = <&aoss1_trip>;
				cooling-device = <&cx_cdev 0 0>;
			};
			mx_vdd_cdev {
				trip = <&aoss1_trip>;
				cooling-device = <&mx_cdev 0 0>;
			};
			ebi_vdd_cdev {
				trip = <&aoss1_trip>;
				cooling-device = <&ebi_cdev 0 0>;
			};
			modem_vdd_cdev {
				trip = <&aoss1_trip>;
				cooling-device = <&modem_vdd 0 0>;
			};
			adsp_vdd_cdev {
				trip = <&aoss1_trip>;
				cooling-device = <&adsp_vdd 0 0>;
			};
			cdsp_vdd_cdev {
				trip = <&aoss1_trip>;
				cooling-device = <&cdsp_vdd 0 0>;
			};
			slpi_vdd_cdev {
				trip = <&aoss1_trip>;
				cooling-device = <&slpi_vdd 0 0>;
			};
		};
	};

	mdm-dsp-lowf {
		polling-delay-passive = <0>;
		polling-delay = <0>;
		thermal-governor = "low_limits_floor";
		thermal-sensors = <&tsens1 1>;
		wake-capable-sensor;
		tracks-low;
		trips {
			dsp_trip: dsp-trip {
				temperature = <5000>;
				hysteresis = <5000>;
				type = "passive";
			};
		};
		cooling-maps {
			cpu0_vdd_cdev {
				trip = <&dsp_trip>;
				cooling-device = <&CPU0 4 4>;
			};
			cpu4_vdd_cdev {
				trip = <&dsp_trip>;
				cooling-device = <&CPU4 9 9>;
			};
			gpu_vdd_cdev {
				trip = <&dsp_trip>;
				cooling-device = <&msm_gpu 1 1>;
			};
			cx_vdd_cdev {
				trip = <&dsp_trip>;
				cooling-device = <&cx_cdev 0 0>;
			};
			mx_vdd_cdev {
				trip = <&dsp_trip>;
				cooling-device = <&mx_cdev 0 0>;
			};
			ebi_vdd_cdev {
				trip = <&dsp_trip>;
				cooling-device = <&ebi_cdev 0 0>;
			};
			modem_vdd_cdev {
				trip = <&dsp_trip>;
				cooling-device = <&modem_vdd 0 0>;
			};
			adsp_vdd_cdev {
				trip = <&dsp_trip>;
				cooling-device = <&adsp_vdd 0 0>;
			};
			cdsp_vdd_cdev {
				trip = <&dsp_trip>;
				cooling-device = <&cdsp_vdd 0 0>;
			};
			slpi_vdd_cdev {
				trip = <&dsp_trip>;
				cooling-device = <&slpi_vdd 0 0>;
			};
		};
	};

	ddr-lowf {
		polling-delay-passive = <0>;
		polling-delay = <0>;
		thermal-governor = "low_limits_floor";
		thermal-sensors = <&tsens1 2>;
		wake-capable-sensor;
		tracks-low;
		trips {
			ddr_trip: ddr-trip {
				temperature = <5000>;
				hysteresis = <5000>;
				type = "passive";
			};
		};
		cooling-maps {
			cpu0_vdd_cdev {
				trip = <&ddr_trip>;
				cooling-device = <&CPU0 4 4>;
			};
			cpu4_vdd_cdev {
				trip = <&ddr_trip>;
				cooling-device = <&CPU4 9 9>;
			};
			gpu_vdd_cdev {
				trip = <&ddr_trip>;
				cooling-device = <&msm_gpu 1 1>;
			};
			cx_vdd_cdev {
				trip = <&ddr_trip>;
				cooling-device = <&cx_cdev 0 0>;
			};
			mx_vdd_cdev {
				trip = <&ddr_trip>;
				cooling-device = <&mx_cdev 0 0>;
			};
			ebi_vdd_cdev {
				trip = <&ddr_trip>;
				cooling-device = <&ebi_cdev 0 0>;
			};
			modem_vdd_cdev {
				trip = <&ddr_trip>;
				cooling-device = <&modem_vdd 0 0>;
			};
			adsp_vdd_cdev {
				trip = <&ddr_trip>;
				cooling-device = <&adsp_vdd 0 0>;
			};
			cdsp_vdd_cdev {
				trip = <&ddr_trip>;
				cooling-device = <&cdsp_vdd 0 0>;
			};
			slpi_vdd_cdev {
				trip = <&ddr_trip>;
				cooling-device = <&slpi_vdd 0 0>;
			};
		};
	};

	wlan-lowf {
		polling-delay-passive = <0>;
		polling-delay = <0>;
		thermal-governor = "low_limits_floor";
		thermal-sensors = <&tsens1 3>;
		wake-capable-sensor;
		tracks-low;
		trips {
			wlan_trip: wlan-trip {
				temperature = <5000>;
				hysteresis = <5000>;
				type = "passive";
			};
		};
		cooling-maps {
			cpu0_vdd_cdev {
				trip = <&wlan_trip>;
				cooling-device = <&CPU0 4 4>;
			};
			cpu4_vdd_cdev {
				trip = <&wlan_trip>;
				cooling-device = <&CPU4 9 9>;
			};
			gpu_vdd_cdev {
				trip = <&wlan_trip>;
				cooling-device = <&msm_gpu 1 1>;
			};
			cx_vdd_cdev {
				trip = <&wlan_trip>;
				cooling-device = <&cx_cdev 0 0>;
			};
			mx_vdd_cdev {
				trip = <&wlan_trip>;
				cooling-device = <&mx_cdev 0 0>;
			};
			ebi_vdd_cdev {
				trip = <&wlan_trip>;
				cooling-device = <&ebi_cdev 0 0>;
			};
			modem_vdd_cdev {
				trip = <&wlan_trip>;
				cooling-device = <&modem_vdd 0 0>;
			};
			adsp_vdd_cdev {
				trip = <&wlan_trip>;
				cooling-device = <&adsp_vdd 0 0>;
			};
			cdsp_vdd_cdev {
				trip = <&wlan_trip>;
				cooling-device = <&cdsp_vdd 0 0>;
			};
			slpi_vdd_cdev {
				trip = <&wlan_trip>;
				cooling-device = <&slpi_vdd 0 0>;
			};
		};
	};

	compute-hvx-lowf {
		polling-delay-passive = <0>;
		polling-delay = <0>;
		thermal-governor = "low_limits_floor";
		thermal-sensors = <&tsens1 4>;
		wake-capable-sensor;
		tracks-low;
		trips {
			hvx_trip: hvx-trip {
				temperature = <5000>;
				hysteresis = <5000>;
				type = "passive";
			};
		};
		cooling-maps {
			cpu0_vdd_cdev {
				trip = <&hvx_trip>;
				cooling-device = <&CPU0 4 4>;
			};
			cpu4_vdd_cdev {
				trip = <&hvx_trip>;
				cooling-device = <&CPU4 9 9>;
			};
			gpu_vdd_cdev {
				trip = <&hvx_trip>;
				cooling-device = <&msm_gpu 1 1>;
			};
			cx_vdd_cdev {
				trip = <&hvx_trip>;
				cooling-device = <&cx_cdev 0 0>;
			};
			mx_vdd_cdev {
				trip = <&hvx_trip>;
				cooling-device = <&mx_cdev 0 0>;
			};
			ebi_vdd_cdev {
				trip = <&hvx_trip>;
				cooling-device = <&ebi_cdev 0 0>;
			};
			modem_vdd_cdev {
				trip = <&hvx_trip>;
				cooling-device = <&modem_vdd 0 0>;
			};
			adsp_vdd_cdev {
				trip = <&hvx_trip>;
				cooling-device = <&adsp_vdd 0 0>;
			};
			cdsp_vdd_cdev {
				trip = <&hvx_trip>;
				cooling-device = <&cdsp_vdd 0 0>;
			};
			slpi_vdd_cdev {
				trip = <&hvx_trip>;
				cooling-device = <&slpi_vdd 0 0>;
			};
		};
	};

	camera-lowf {
		polling-delay-passive = <0>;
		polling-delay = <0>;
		thermal-governor = "low_limits_floor";
		thermal-sensors = <&tsens1 5>;
		wake-capable-sensor;
		tracks-low;
		trips {
			camera_trip: camera-trip {
				temperature = <5000>;
				hysteresis = <5000>;
				type = "passive";
			};
		};
		cooling-maps {
			cpu0_vdd_cdev {
				trip = <&camera_trip>;
				cooling-device = <&CPU0 4 4>;
			};
			cpu4_vdd_cdev {
				trip = <&camera_trip>;
				cooling-device = <&CPU4 9 9>;
			};
			gpu_vdd_cdev {
				trip = <&camera_trip>;
				cooling-device = <&msm_gpu 1 1>;
			};
			cx_vdd_cdev {
				trip = <&camera_trip>;
				cooling-device = <&cx_cdev 0 0>;
			};
			mx_vdd_cdev {
				trip = <&camera_trip>;
				cooling-device = <&mx_cdev 0 0>;
			};
			ebi_vdd_cdev {
				trip = <&camera_trip>;
				cooling-device = <&ebi_cdev 0 0>;
			};
			modem_vdd_cdev {
				trip = <&camera_trip>;
				cooling-device = <&modem_vdd 0 0>;
			};
			adsp_vdd_cdev {
				trip = <&camera_trip>;
				cooling-device = <&adsp_vdd 0 0>;
			};
			cdsp_vdd_cdev {
				trip = <&camera_trip>;
				cooling-device = <&cdsp_vdd 0 0>;
			};
			slpi_vdd_cdev {
				trip = <&camera_trip>;
				cooling-device = <&slpi_vdd 0 0>;
			};
		};
	};

	mmss-lowf {
		polling-delay-passive = <0>;
		polling-delay = <0>;
		thermal-governor = "low_limits_floor";
		thermal-sensors = <&tsens1 6>;
		wake-capable-sensor;
		tracks-low;
		trips {
			mmss_trip: mmss-trip {
				temperature = <5000>;
				hysteresis = <5000>;
				type = "passive";
			};
		};
		cooling-maps {
			cpu0_vdd_cdev {
				trip = <&mmss_trip>;
				cooling-device = <&CPU0 4 4>;
			};
			cpu4_vdd_cdev {
				trip = <&mmss_trip>;
				cooling-device = <&CPU4 9 9>;
			};
			gpu_vdd_cdev {
				trip = <&mmss_trip>;
				cooling-device = <&msm_gpu 1 1>;
			};
			cx_vdd_cdev {
				trip = <&mmss_trip>;
				cooling-device = <&cx_cdev 0 0>;
			};
			mx_vdd_cdev {
				trip = <&mmss_trip>;
				cooling-device = <&mx_cdev 0 0>;
			};
			ebi_vdd_cdev {
				trip = <&mmss_trip>;
				cooling-device = <&ebi_cdev 0 0>;
			};
			modem_vdd_cdev {
				trip = <&mmss_trip>;
				cooling-device = <&modem_vdd 0 0>;
			};
			adsp_vdd_cdev {
				trip = <&mmss_trip>;
				cooling-device = <&adsp_vdd 0 0>;
			};
			cdsp_vdd_cdev {
				trip = <&mmss_trip>;
				cooling-device = <&cdsp_vdd 0 0>;
			};
			slpi_vdd_cdev {
				trip = <&mmss_trip>;
				cooling-device = <&slpi_vdd 0 0>;
			};
		};
	};

	mdm-core-lowf {
		polling-delay-passive = <0>;
		polling-delay = <0>;
		thermal-governor = "low_limits_floor";
		thermal-sensors = <&tsens1 7>;
		wake-capable-sensor;
		tracks-low;
		trips {
			mdm_trip: mdm-trip {
				temperature = <5000>;
				hysteresis = <5000>;
				type = "passive";
			};
		};
		cooling-maps {
			cpu0_vdd_cdev {
				trip = <&mdm_trip>;
				cooling-device = <&CPU0 4 4>;
			};
			cpu4_vdd_cdev {
				trip = <&mdm_trip>;
				cooling-device = <&CPU4 9 9>;
			};
			gpu_vdd_cdev {
				trip = <&mdm_trip>;
				cooling-device = <&msm_gpu 1 1>;
			};
			cx_vdd_cdev {
				trip = <&mdm_trip>;
				cooling-device = <&cx_cdev 0 0>;
			};
			mx_vdd_cdev {
				trip = <&mdm_trip>;
				cooling-device = <&mx_cdev 0 0>;
			};
			ebi_vdd_cdev {
				trip = <&mdm_trip>;
				cooling-device = <&ebi_cdev 0 0>;
			};
			modem_vdd_cdev {
				trip = <&mdm_trip>;
				cooling-device = <&modem_vdd 0 0>;
			};
			adsp_vdd_cdev {
				trip = <&mdm_trip>;
				cooling-device = <&adsp_vdd 0 0>;
			};
			cdsp_vdd_cdev {
				trip = <&mdm_trip>;
				cooling-device = <&cdsp_vdd 0 0>;
			};
			slpi_vdd_cdev {
				trip = <&mdm_trip>;
				cooling-device = <&slpi_vdd 0 0>;
			};
		};
	};
};
